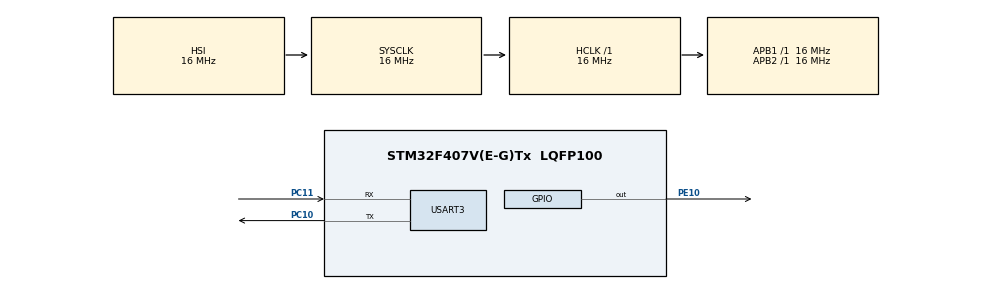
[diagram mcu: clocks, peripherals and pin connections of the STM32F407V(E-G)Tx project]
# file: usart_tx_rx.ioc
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Dma.Request0=USART3_TX
Dma.USART3_TX.0.Direction=DMA_MEMORY_TO_PERIPH
Dma.USART3_TX.0.FIFOMode=DMA_FIFOMODE_DISABLE
Dma.USART3_TX.0.Instance=DMA1_Stream3
Dma.USART3_TX.0.MemDataAlignment=DMA_MDATAALIGN_BYTE
Dma.USART3_TX.0.MemInc=DMA_MINC_ENABLE
Dma.USART3_TX.0.Mode=DMA_NORMAL
Dma.USART3_TX.0.PeriphDataAlignment=DMA_PDATAALIGN_BYTE
Dma.USART3_TX.0.PeriphInc=DMA_PINC_DISABLE
Dma.USART3_TX.0.Priority=DMA_PRIORITY_LOW
FREERTOS.Tasks01=defaultTask,24,128,StartDefaultTask,Default,NULL,Dynamic,NULL,NULL;TransmitTask,10,128,transmit_task,Default,NULL,Dynamic,NULL,NULL
FREERTOS.configUSE_NEWLIB_REENTRANT=1
Mcu.Family=STM32F4
Mcu.Name=STM32F407V(E-G)Tx
Mcu.Package=LQFP100
NVIC.DMA1_Stream3_IRQn=true\:5\:0\:false\:false\:true\:true\:false\:true
NVIC.PriorityGroup=NVIC_PRIORITYGROUP_4
NVIC.TIM6_DAC_IRQn=true\:15\:0\:false\:false\:true\:false\:false\:true
NVIC.TimeBase=TIM6_DAC_IRQn
NVIC.TimeBaseIP=TIM6
NVIC.USART3_IRQn=true\:5\:0\:false\:false\:true\:true\:true\:true
PC10.Mode=Asynchronous
PC10.Signal=USART3_TX
PC11.Mode=Asynchronous
PC11.Signal=USART3_RX
PE10.Signal=GPIO_Output
ProjectManager.HeapSize=0x200
ProjectManager.StackSize=0x400
ProjectManager.TargetToolchain=STM32CubeIDE
RCC.AHBFreq_Value=16000000
RCC.APB1Freq_Value=16000000
RCC.APB2Freq_Value=16000000
RCC.CortexFreq_Value=16000000
RCC.HSE_VALUE=25000000
RCC.HSI_VALUE=16000000
RCC.LSE_VALUE=32768
RCC.SYSCLKFreq_VALUE=16000000
RCC.VCOOutputFreq_Value=192000000
USART3.VirtualMode=VM_ASYNC
VP_FREERTOS_VS_CMSIS_V2.Mode=CMSIS_V2
VP_SYS_VS_tim6.Mode=TIM6
board=custom

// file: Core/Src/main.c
/* USER CODE BEGIN Header */
/**
  ******************************************************************************
  * @file           : main.c
  * @brief          : Main program body
  ******************************************************************************
  * @attention
  *
  * Copyright (c) 2022 STMicroelectronics.
  * All rights reserved.
  *
  * This software is licensed under terms that can be found in the LICENSE file
  * in the root directory of this software component.
  * If no LICENSE file comes with this software, it is provided AS-IS.
  *
  ******************************************************************************
  */
/* USER CODE END Header */
#include "main.h"
#include "cmsis_os.h"

/* USER CODE BEGIN Includes */
#include <string.h>
#include <stdio.h>
/* USER CODE END Includes */

UART_HandleTypeDef huart3;
DMA_HandleTypeDef hdma_usart3_tx;

/* Definitions for defaultTask */
osThreadId_t defaultTaskHandle;
const osThreadAttr_t defaultTask_attributes = {
  .name = "defaultTask",
  .stack_size = 128 * 4,
  .priority = (osPriority_t) osPriorityNormal,
};
/* Definitions for TransmitTask */
osThreadId_t TransmitTaskHandle;
const osThreadAttr_t TransmitTask_attributes = {
  .name = "TransmitTask",
  .stack_size = 128 * 4,
  .priority = (osPriority_t) osPriorityLow2,
};

void SystemClock_Config(void);
static void MX_GPIO_Init(void);
static void MX_USART3_UART_Init(void);
static void MX_DMA_Init(void);
void StartDefaultTask(void *argument);
void transmit_task(void *argument);

/* USER CODE BEGIN 0 */
volatile uint8_t rx_buffer[20] = "Hello World\r\n";
volatile uint8_t inst_buffer[20];
void DMATransferComplete(DMA_HandleTypeDef* hdma);
/* USER CODE END 0 */

int main(void)
{

  /* MCU Configuration--------------------------------------------------------*/

  /* Reset of all peripherals, Initializes the Flash interface and the Systick. */
  HAL_Init();

  /* Configure the system clock */
  SystemClock_Config();

  /* Initialize all configured peripherals */
  MX_GPIO_Init();
  MX_DMA_Init();
  MX_USART3_UART_Init();
  /* USER CODE BEGIN 2 */
  HAL_DMA_RegisterCallback(&hdma_usart3_tx, HAL_DMA_XFER_CPLT_CB_ID, &DMATransferComplete);
  HAL_UART_Receive_IT(&huart3, (uint8_t*)rx_buffer, 10);
  /* USER CODE END 2 */

  /* Init scheduler */
  osKernelInitialize();

  /* Create the thread(s) */
  /* creation of defaultTask */
  defaultTaskHandle = osThreadNew(StartDefaultTask, NULL, &defaultTask_attributes);

  /* creation of TransmitTask */
  TransmitTaskHandle = osThreadNew(transmit_task, NULL, &TransmitTask_attributes);

  /* Start scheduler */
  osKernelStart();

  /* We should never get here as control is now taken by the scheduler */
  /* Infinite loop */
  while (1)
  {

  }
}

void SystemClock_Config(void)
{
  RCC_OscInitTypeDef RCC_OscInitStruct = {0};
  RCC_ClkInitTypeDef RCC_ClkInitStruct = {0};

  /** Configure the main internal regulator output voltage
  */
  __HAL_RCC_PWR_CLK_ENABLE();
  __HAL_PWR_VOLTAGESCALING_CONFIG(PWR_REGULATOR_VOLTAGE_SCALE1);
  /** Initializes the RCC Oscillators according to the specified parameters
  * in the RCC_OscInitTypeDef structure.
  */
  RCC_OscInitStruct.OscillatorType = RCC_OSCILLATORTYPE_HSI;
  RCC_OscInitStruct.HSIState = RCC_HSI_ON;
  RCC_OscInitStruct.HSICalibrationValue = RCC_HSICALIBRATION_DEFAULT;
  RCC_OscInitStruct.PLL.PLLState = RCC_PLL_NONE;
  if (HAL_RCC_OscConfig(&RCC_OscInitStruct) != HAL_OK)
  {
    Error_Handler();
  }
  /** Initializes the CPU, AHB and APB buses clocks
  */
  RCC_ClkInitStruct.ClockType = RCC_CLOCKTYPE_HCLK|RCC_CLOCKTYPE_SYSCLK
                              |RCC_CLOCKTYPE_PCLK1|RCC_CLOCKTYPE_PCLK2;
  RCC_ClkInitStruct.SYSCLKSource = RCC_SYSCLKSOURCE_HSI;
  RCC_ClkInitStruct.AHBCLKDivider = RCC_SYSCLK_DIV1;
  RCC_ClkInitStruct.APB1CLKDivider = RCC_HCLK_DIV1;
  RCC_ClkInitStruct.APB2CLKDivider = RCC_HCLK_DIV1;

  if (HAL_RCC_ClockConfig(&RCC_ClkInitStruct, FLASH_LATENCY_0) != HAL_OK)
  {
    Error_Handler();
  }
}

static void MX_USART3_UART_Init(void)
{

  huart3.Instance = USART3;
  huart3.Init.BaudRate = 115200;
  huart3.Init.WordLength = UART_WORDLENGTH_8B;
  huart3.Init.StopBits = UART_STOPBITS_1;
  huart3.Init.Parity = UART_PARITY_NONE;
  huart3.Init.Mode = UART_MODE_TX_RX;
  huart3.Init.HwFlowCtl = UART_HWCONTROL_NONE;
  huart3.Init.OverSampling = UART_OVERSAMPLING_16;
  if (HAL_UART_Init(&huart3) != HAL_OK)
  {
    Error_Handler();
  }

}

static void MX_DMA_Init(void)
{

  /* DMA controller clock enable */
  __HAL_RCC_DMA1_CLK_ENABLE();

  /* DMA interrupt init */
  /* DMA1_Stream3_IRQn interrupt configuration */
  HAL_NVIC_SetPriority(DMA1_Stream3_IRQn, 5, 0);
  HAL_NVIC_EnableIRQ(DMA1_Stream3_IRQn);

}

static void MX_GPIO_Init(void)
{
  GPIO_InitTypeDef GPIO_InitStruct = {0};

  /* GPIO Ports Clock Enable */
  __HAL_RCC_GPIOE_CLK_ENABLE();
  __HAL_RCC_GPIOC_CLK_ENABLE();

  /*Configure GPIO pin Output Level */
  HAL_GPIO_WritePin(GPIOE, GPIO_PIN_10, GPIO_PIN_RESET);

  /*Configure GPIO pin : PE10 */
  GPIO_InitStruct.Pin = GPIO_PIN_10;
  GPIO_InitStruct.Mode = GPIO_MODE_OUTPUT_PP;
  GPIO_InitStruct.Pull = GPIO_NOPULL;
  GPIO_InitStruct.Speed = GPIO_SPEED_FREQ_LOW;
  HAL_GPIO_Init(GPIOE, &GPIO_InitStruct);

}

/* USER CODE BEGIN 4 */
// Callback function for when USART DMA transmit is done
void DMATransferComplete(DMA_HandleTypeDef* hdma)
{
		// Disable the DMA
		huart3.Instance->CR3 &= ~USART_CR3_DMAT;
		  HAL_GPIO_TogglePin(GPIOE, GPIO_PIN_10);
}

void HAL_UART_RxCpltCallback(UART_HandleTypeDef* huart)
{
//	UNUSED(huart);
//	HAL_GPIO_TogglePin(GPIOE, GPIO_PIN_10);
	memcpy(inst_buffer, rx_buffer, 10);
	inst_buffer[10] = '\n';
	HAL_UART_Receive_IT(&huart3, (uint8_t*)rx_buffer, 10);
}
/* USER CODE END 4 */

void StartDefaultTask(void *argument)
{
  for(;;)
  {
    osDelay(1);
  }
}

void transmit_task(void *argument)
{
  /* USER CODE BEGIN transmit_task */
  /* Infinite loop */
  for(;;)
  {
		// Enable the DMA to start a transfer process
		huart3.Instance->CR3 |= USART_CR3_DMAT;
//	  HAL_UART_Transmit_DMA(&huart3, (uint8_t*)msg, sizeof(msg));
		HAL_DMA_Start_IT(&hdma_usart3_tx, (uint32_t)inst_buffer,
				(uint32_t)&huart3.Instance->DR, sizeof(inst_buffer));
    osDelay(3000);
  }
  /* USER CODE END transmit_task */
}

void HAL_TIM_PeriodElapsedCallback(TIM_HandleTypeDef *htim)
{
  if (htim->Instance == TIM6) {
    HAL_IncTick();
  }
}

void Error_Handler(void)
{
  __disable_irq();
  while (1)
  {
  }
}
